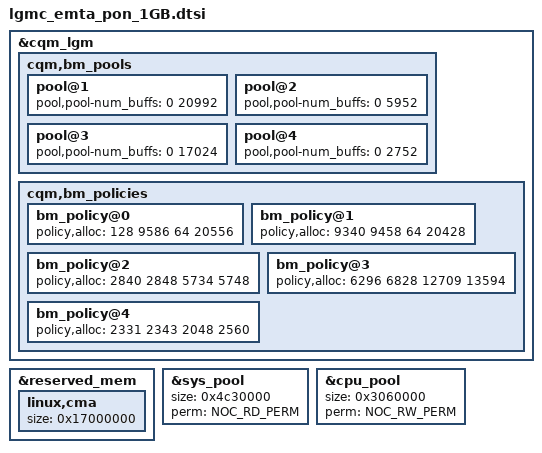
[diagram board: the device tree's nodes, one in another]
// SPDX-License-Identifier: GPL-2.0
/*
 * Copyright (C) 2024 MaxLinear, Inc.
 *
 * This program is free software; you can redistribute it and/or modify it
 * under the terms of the GNU General Public License, as published by the Free
 * Software Foundation; either version 2 of the License, or (at your option)
 * any later version.
 *
 * This program is distributed in the hope that it will be useful, but WITHOUT
 * ANY WARRANTY; without even the implied warranty of MERCHANTABILITY or
 * FITNESS FOR A PARTICULAR PURPOSE.
 * See the GNU General Public License for more details.
 *
 * You should have received a copy of the GNU General Public License along
 * with this program; if not, see <http://www.gnu.org/licenses/>.
 */

&cqm_lgm {
	/delete-node/ mxl,wav-port-resv;
	//same for eth wan, pon and docsis
	cqm,bm_pools {
		pool@1 {
			pool,pool-num_buffs = <0 20992>;
		};
		pool@2 {
			pool,pool-num_buffs = <0 5952>;
		};
		pool@3 {
			pool,pool-num_buffs = <0 17024>;
		};
		pool@4 {
			pool,pool-num_buffs = <0 2752>;
		};
	};
	// emta same as eth wan
	cqm,bm_policies {
		/delete-node/ bm_policy@6;
		/delete-node/ bm_policy@7;
		/delete-node/ bm_policy@8;
		/delete-node/ bm_policy@9;
		/delete-node/ bm_policy@10;
		/delete-node/ bm_policy@11;
		/delete-node/ bm_policy@12;
		/delete-node/ bm_policy@13;
		/delete-node/ bm_policy@14;
		/delete-node/ bm_policy@15;
		/delete-node/ bm_policy@16;
		/delete-node/ bm_policy@22;
		/delete-node/ bm_policy@23;
		/delete-node/ bm_policy@24;
		/delete-node/ bm_policy@25;
		/delete-node/ bm_policy@26;
		/delete-node/ bm_policy@27;
		/delete-node/ bm_policy@28;
		/delete-node/ bm_policy@29;
		/delete-node/ bm_policy@30;

		bm_policy@0 {
			policy,alloc = <128 9586 64 20556>;
		};
		bm_policy@1 {
			policy,alloc = <9340 9458 64 20428>;
		};
		bm_policy@2 {
			policy,alloc = <2840 2848 5734 5748>;
		};
		bm_policy@3 {
			policy,alloc = <6296 6828 12709 13594>;
		};
		bm_policy@4 {
			policy,alloc = <2331 2343 2048 2560>;
		};
	};
};

&reserved_mem {
	linux,cma {
		size = <0x17000000>;
	};
};

&sys_pool {
	size = <0x4c30000>;
	perm = <NOC_RD_PERM>;
};

&cpu_pool {
	size = <0x3060000>;
	perm = <NOC_RW_PERM>;
};
